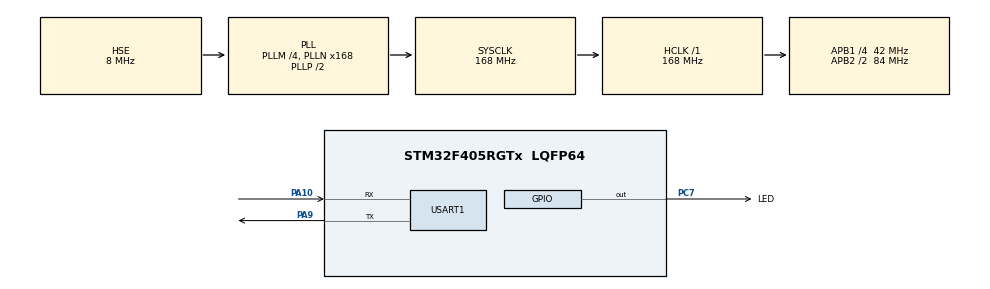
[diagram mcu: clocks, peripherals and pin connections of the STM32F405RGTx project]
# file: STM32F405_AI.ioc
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Mcu.Family=STM32F4
Mcu.Name=STM32F405RGTx
Mcu.Package=LQFP64
NVIC.PriorityGroup=NVIC_PRIORITYGROUP_4
NVIC.USART1_IRQn=true\:0\:0\:false\:false\:true\:true
PA10.Mode=Asynchronous
PA10.Signal=USART1_RX
PA13.Mode=Serial_Wire
PA13.Signal=SYS_JTMS-SWDIO
PA14.Mode=Serial_Wire
PA14.Signal=SYS_JTCK-SWCLK
PA9.Mode=Asynchronous
PA9.Signal=USART1_TX
PC7.GPIO_Label=LED
PC7.GPIO_PuPd=GPIO_PULLDOWN
PC7.PinState=GPIO_PIN_RESET
PC7.Signal=GPIO_Output
PH0-OSC_IN.Mode=HSE-External-Oscillator
PH0-OSC_IN.Signal=RCC_OSC_IN
PH1-OSC_OUT.Mode=HSE-External-Oscillator
PH1-OSC_OUT.Signal=RCC_OSC_OUT
ProjectManager.HeapSize=0x2000
ProjectManager.StackSize=0x4000
ProjectManager.TargetToolchain=TrueSTUDIO
RCC.48MHZClocksFreq_Value=84000000
RCC.AHBFreq_Value=168000000
RCC.APB1CLKDivider=RCC_HCLK_DIV4
RCC.APB1Freq_Value=42000000
RCC.APB1TimFreq_Value=84000000
RCC.APB2CLKDivider=RCC_HCLK_DIV2
RCC.APB2Freq_Value=84000000
RCC.APB2TimFreq_Value=168000000
RCC.CortexFreq_Value=168000000
RCC.HCLKFreq_Value=168000000
RCC.HSE_VALUE=8000000
RCC.HSI_VALUE=16000000
RCC.LSE_VALUE=32768
RCC.PLLM=4
RCC.PLLN=168
RCC.PLLSourceVirtual=RCC_PLLSOURCE_HSE
RCC.SYSCLKFreq_VALUE=168000000
RCC.SYSCLKSource=RCC_SYSCLKSOURCE_PLLCLK
RCC.VCOOutputFreq_Value=336000000
STMicroelectronics.X-CUBE-AI.3.3.0.ApplicationCcArtificialOoIntelligenceJjApplication=ApplicationTemplate
STMicroelectronics.X-CUBE-AI.3.3.0.ArtificialOoIntelligenceJjApplication.cmp_version0=3.3.0
STMicroelectronics.X-CUBE-AI.3.3.0.ArtificialOoIntelligenceJjApplication.component0=Artificial Intelligence
STMicroelectronics.X-CUBE-AI.3.3.0.ArtificialOoIntelligenceJjApplication.description0=AI Application,Application Template
STMicroelectronics.X-CUBE-AI.3.3.0.ArtificialOoIntelligenceJjApplication.diagnostic0=This component should operate correctly.
STMicroelectronics.X-CUBE-AI.3.3.0.ArtificialOoIntelligenceJjApplication.documentation0=readme.txt
STMicroelectronics.X-CUBE-AI.3.3.0.ArtificialOoIntelligenceJjApplication.group0=Application
STMicroelectronics.X-CUBE-AI.3.3.0.ArtificialOoIntelligenceJjApplication.paramName0=ApplicationCcArtificialOoIntelligenceJjApplication
STMicroelectronics.X-CUBE-AI.3.3.0.ArtificialOoIntelligenceJjApplication.sevirity0=none
STMicroelectronics.X-CUBE-AI.3.3.0.ArtificialOoIntelligenceJjApplication.variant0=ApplicationTemplate
STMicroelectronics.X-CUBE-AI.3.3.0.ArtificialOoIntelligenceJjApplication_bundle=Application
STMicroelectronics.X-CUBE-AI.3.3.0.ArtificialOoIntelligenceJjApplication_class=ArtificialOoIntelligence
STMicroelectronics.X-CUBE-AI.3.3.0.ArtificialOoIntelligenceJjApplication_name=X-CUBE-AI
STMicroelectronics.X-CUBE-AI.3.3.0.ArtificialOoIntelligenceJjApplication_size=1
STMicroelectronics.X-CUBE-AI.3.3.0.ArtificialOoIntelligenceJjApplication_vendor=STMicroelectronics
STMicroelectronics.X-CUBE-AI.3.3.0.ArtificialOoIntelligenceJjApplication_version=3.3.0
STMicroelectronics.X-CUBE-AI.3.3.0.ArtificialOoIntelligenceJjCore.cmp_version0=3.3.0
STMicroelectronics.X-CUBE-AI.3.3.0.ArtificialOoIntelligenceJjCore.component0=Artificial Intelligence
STMicroelectronics.X-CUBE-AI.3.3.0.ArtificialOoIntelligenceJjCore.description0=AI Core,Artificial Intelligence for STM32
STMicroelectronics.X-CUBE-AI.3.3.0.ArtificialOoIntelligenceJjCore.diagnostic0=This component should operate correctly.
STMicroelectronics.X-CUBE-AI.3.3.0.ArtificialOoIntelligenceJjCore.documentation0=readme.txt
STMicroelectronics.X-CUBE-AI.3.3.0.ArtificialOoIntelligenceJjCore.group0=CORE
STMicroelectronics.X-CUBE-AI.3.3.0.ArtificialOoIntelligenceJjCore.paramName0=CoreCcArtificialOoIntelligenceJjCORE
STMicroelectronics.X-CUBE-AI.3.3.0.ArtificialOoIntelligenceJjCore.sevirity0=none
STMicroelectronics.X-CUBE-AI.3.3.0.ArtificialOoIntelligenceJjCore_bundle=Core
STMicroelectronics.X-CUBE-AI.3.3.0.ArtificialOoIntelligenceJjCore_class=ArtificialOoIntelligence
STMicroelectronics.X-CUBE-AI.3.3.0.ArtificialOoIntelligenceJjCore_name=X-CUBE-AI
STMicroelectronics.X-CUBE-AI.3.3.0.ArtificialOoIntelligenceJjCore_size=1
STMicroelectronics.X-CUBE-AI.3.3.0.ArtificialOoIntelligenceJjCore_vendor=STMicroelectronics
STMicroelectronics.X-CUBE-AI.3.3.0.ArtificialOoIntelligenceJjCore_version=3.3.0
STMicroelectronics.X-CUBE-AI.3.3.0.CoreCcArtificialOoIntelligenceJjCORE=true
STMicroelectronics.X-CUBE-AI.3.3.0_ArtificialOoIntelligenceJjApplication_RteComponent0=\#define AI_ApplicationTemplate
STMicroelectronics.X-CUBE-AI.3.3.0_ArtificialOoIntelligenceJjApplication_RteComponentsize=1
STMicroelectronics.X-CUBE-AI.3.3.0_ArtificialOoIntelligenceJjCore_RteComponentsize=0
STMicroelectronics.X-CUBE-AI.3.3.0_MwName0=Core
STMicroelectronics.X-CUBE-AI.3.3.0_MwName1=Application
STMicroelectronics.X-CUBE-AI.3.3.0_NumberOfMw=2
STMicroelectronics.X-CUBE-AI.3.3.0_description=Artificial Intelligence
STMicroelectronics.X-CUBE-AI.3.3.0_license=SLA0048.txt
USART1.VirtualMode=VM_ASYNC
VP_CRC_VS_CRC.Mode=CRC_Activate
VP_STMicroelectronics.X-CUBE-AI_VS_ArtificialOoIntelligenceJjCore_3.3.0.Mode=ArtificialOoIntelligenceJjCore
board=custom

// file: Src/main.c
/* USER CODE BEGIN Header */
/**
  ******************************************************************************
  * @file           : main.c
  * @brief          : Main program body
  ******************************************************************************
  * This notice applies to any and all portions of this file
  * that are not between comment pairs USER CODE BEGIN and
  * USER CODE END. Other portions of this file, whether
  * inserted by the user or by software development tools
  * are owned by their respective copyright owners.
  *
  * Copyright (c) 2019 STMicroelectronics International N.V.
  * All rights reserved.
  *
  * Redistribution and use in source and binary forms, with or without
  * modification, are permitted, provided that the following conditions are met:
  *
  * 1. Redistribution of source code must retain the above copyright notice,
  *    this list of conditions and the following disclaimer.
  * 2. Redistributions in binary form must reproduce the above copyright notice,
  *    this list of conditions and the following disclaimer in the documentation
  *    and/or other materials provided with the distribution.
  * 3. Neither the name of STMicroelectronics nor the names of other
  *    contributors to this software may be used to endorse or promote products
  *    derived from this software without specific written permission.
  * 4. This software, including modifications and/or derivative works of this
  *    software, must execute solely and exclusively on microcontroller or
  *    microprocessor devices manufactured by or for STMicroelectronics.
  * 5. Redistribution and use of this software other than as permitted under
  *    this license is void and will automatically terminate your rights under
  *    this license.
  *
  * THIS SOFTWARE IS PROVIDED BY STMICROELECTRONICS AND CONTRIBUTORS "AS IS"
  * AND ANY EXPRESS, IMPLIED OR STATUTORY WARRANTIES, INCLUDING, BUT NOT
  * LIMITED TO, THE IMPLIED WARRANTIES OF MERCHANTABILITY, FITNESS FOR A
  * PARTICULAR PURPOSE AND NON-INFRINGEMENT OF THIRD PARTY INTELLECTUAL PROPERTY
  * RIGHTS ARE DISCLAIMED TO THE FULLEST EXTENT PERMITTED BY LAW. IN NO EVENT
  * SHALL STMICROELECTRONICS OR CONTRIBUTORS BE LIABLE FOR ANY DIRECT, INDIRECT,
  * INCIDENTAL, SPECIAL, EXEMPLARY, OR CONSEQUENTIAL DAMAGES (INCLUDING, BUT NOT
  * LIMITED TO, PROCUREMENT OF SUBSTITUTE GOODS OR SERVICES; LOSS OF USE, DATA,
  * OR PROFITS; OR BUSINESS INTERRUPTION) HOWEVER CAUSED AND ON ANY THEORY OF
  * LIABILITY, WHETHER IN CONTRACT, STRICT LIABILITY, OR TORT (INCLUDING
  * NEGLIGENCE OR OTHERWISE) ARISING IN ANY WAY OUT OF THE USE OF THIS SOFTWARE,
  * EVEN IF ADVISED OF THE POSSIBILITY OF SUCH DAMAGE.
  *
  ******************************************************************************
  */
/* USER CODE END Header */

#include "main.h"
#include "crc.h"
#include "usart.h"
#include "gpio.h"
#include "app_x-cube-ai.h"

/* USER CODE BEGIN Includes */
#include <string.h>
/* USER CODE END Includes */

/* USER CODE BEGIN PV */
extern UART_HandleTypeDef huart1;
volatile uint8_t AI_PROCESS = 0;
volatile uint8_t GET_DATA = 0;
/* USER CODE END PV */

void SystemClock_Config(void);
/* USER CODE BEGIN PFP */

void HandleUARTCommand(char * CMD_String, int String_Length)
{
	//HAL_UART_Transmit(&huart1, (uint8_t *)CMD_String, String_Length, 100);
	if (strncmp(CMD_String,"AI-DEVICE",9)==0){
		while (HAL_UART_Transmit(&huart1, (uint8_t *)("OK\r\n"), 2, 1000) != HAL_OK){};
	}
	else if (strncmp(CMD_String,"START-TEST",10)==0){
		__HAL_UART_DISABLE_IT(&huart1, UART_IT_RXNE);
		//HAL_UART_Transmit(&huart1, (uint8_t *)("OK\r\n"), 2, 1000);
		//HAL_UART_Receive(&huart1,(uint8_t *)pfData,256,5000);
		GET_DATA = 1;
		//__HAL_UART_ENABLE_IT(&huart1, UART_IT_RXNE);
	}
	else{
		HAL_UART_Transmit(&huart1, (uint8_t *)CMD_String, String_Length, 100);
	}
}
/* USER CODE END PFP */

int main(void)
{

  /* MCU Configuration--------------------------------------------------------*/

  /* Reset of all peripherals, Initializes the Flash interface and the Systick. */
  HAL_Init();

  /* Configure the system clock */
  SystemClock_Config();

  /* Initialize all configured peripherals */
  MX_GPIO_Init();
  MX_USART1_UART_Init();
  MX_CRC_Init();
  MX_X_CUBE_AI_Init();

  __HAL_UART_ENABLE_IT(&huart1, UART_IT_RXNE);
  /* USER CODE BEGIN 2 */
  //ai_float in_data[64];
  ai_float out_data[AI_NETWORK_1_OUT_1_SIZE];
  ai_u16 batch_size = 1;
  //uint8_t pData[256];
  ai_float pfData[AI_NETWORK_1_IN_1_SIZE];
  /* USER CODE END 2 */

  /* Infinite loop */
  while (1)
  {
	  if (GET_DATA==1){
		  while (HAL_UART_Transmit(&huart1, (uint8_t *)("OK\r\n"), 2, 1000) != HAL_OK){};
		  while (HAL_UART_Receive(&huart1, (uint8_t *)pfData, AI_NETWORK_1_IN_1_SIZE*sizeof(ai_float), 5000) != HAL_OK){};
		  GET_DATA = 0;
		  AI_PROCESS = 1;
	  }
	  if (AI_PROCESS == 1)
	  {
		  //while (HAL_UART_Transmit(&huart1, (uint8_t *)pfData, AI_NETWORK_1_IN_1_SIZE*sizeof(ai_float), 5000) != HAL_OK){};
		  MX_X_CUBE_AI_Process((const ai_float *)pfData, out_data, batch_size);
		  while (HAL_UART_Transmit(&huart1, (uint8_t *)out_data, AI_NETWORK_1_OUT_1_SIZE*sizeof(ai_float), 5000) != HAL_OK){};
		  AI_PROCESS = 0;
		  __HAL_UART_ENABLE_IT(&huart1, UART_IT_RXNE);
	  }
  }
}

void SystemClock_Config(void)
{
  RCC_OscInitTypeDef RCC_OscInitStruct = {0};
  RCC_ClkInitTypeDef RCC_ClkInitStruct = {0};

  /**Configure the main internal regulator output voltage
  */
  __HAL_RCC_PWR_CLK_ENABLE();
  __HAL_PWR_VOLTAGESCALING_CONFIG(PWR_REGULATOR_VOLTAGE_SCALE1);
  /**Initializes the CPU, AHB and APB busses clocks
  */
  RCC_OscInitStruct.OscillatorType = RCC_OSCILLATORTYPE_HSE;
  RCC_OscInitStruct.HSEState = RCC_HSE_ON;
  RCC_OscInitStruct.PLL.PLLState = RCC_PLL_ON;
  RCC_OscInitStruct.PLL.PLLSource = RCC_PLLSOURCE_HSE;
  RCC_OscInitStruct.PLL.PLLM = 4;
  RCC_OscInitStruct.PLL.PLLN = 168;
  RCC_OscInitStruct.PLL.PLLP = RCC_PLLP_DIV2;
  RCC_OscInitStruct.PLL.PLLQ = 4;
  if (HAL_RCC_OscConfig(&RCC_OscInitStruct) != HAL_OK)
  {
    Error_Handler();
  }
  /**Initializes the CPU, AHB and APB busses clocks
  */
  RCC_ClkInitStruct.ClockType = RCC_CLOCKTYPE_HCLK|RCC_CLOCKTYPE_SYSCLK
                              |RCC_CLOCKTYPE_PCLK1|RCC_CLOCKTYPE_PCLK2;
  RCC_ClkInitStruct.SYSCLKSource = RCC_SYSCLKSOURCE_PLLCLK;
  RCC_ClkInitStruct.AHBCLKDivider = RCC_SYSCLK_DIV1;
  RCC_ClkInitStruct.APB1CLKDivider = RCC_HCLK_DIV4;
  RCC_ClkInitStruct.APB2CLKDivider = RCC_HCLK_DIV2;

  if (HAL_RCC_ClockConfig(&RCC_ClkInitStruct, FLASH_LATENCY_5) != HAL_OK)
  {
    Error_Handler();
  }
}

void Error_Handler(void)
{
}

/************************ (C) COPYRIGHT STMicroelectronics *****END OF FILE****/
